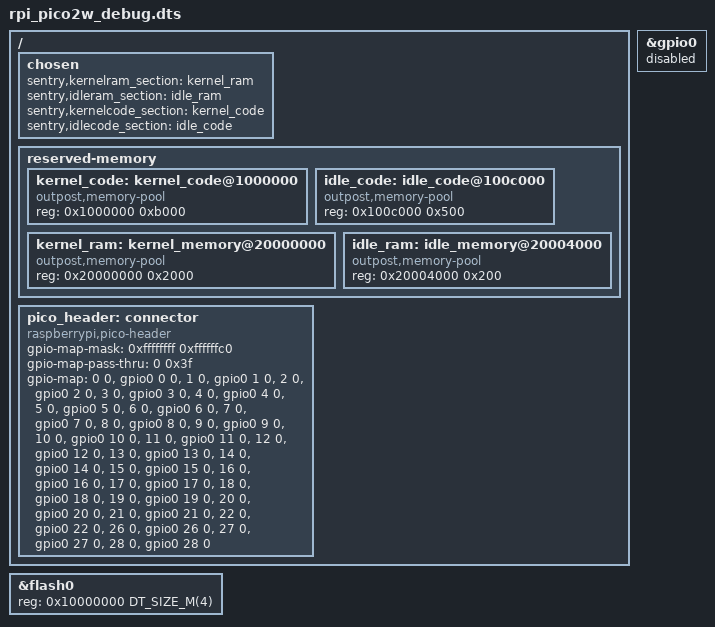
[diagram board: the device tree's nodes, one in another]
/*
 * Copyright (c) 2025 H2Lab development Team
 *
 * SPDX-License-Identifier: Apache-2.0
 */

/{
	chosen {
		sentry,kernelram_section = <&kernel_ram>;
		sentry,idleram_section = <&idle_ram>;
		sentry,kernelcode_section = <&kernel_code>;
		sentry,idlecode_section = <&idle_code>;
	};

	reserved-memory {
		#address-cells = <1>;
		#size-cells = <1>;

		kernel_code: kernel_code@1000000 {
			reg = <0x1000000 0xb000>;
			compatible = "outpost,memory-pool";
		};

		idle_code: idle_code@100c000 {
			reg = <0x100c000 0x500>;
			compatible = "outpost,memory-pool";
		};

		kernel_ram: kernel_memory@20000000 {
			reg = <0x20000000 0x2000>;
			compatible = "outpost,memory-pool";
		};

		idle_ram: idle_memory@20004000 {
			reg = <0x20004000 0x200>;
			compatible = "outpost,memory-pool";
		};
	};

    pico_header: connector {
            compatible = "raspberrypi,pico-header";
            #gpio-cells = <2>;
            gpio-map-mask = <0xffffffff 0xffffffc0>;
            gpio-map-pass-thru = <0 0x3f>;
            gpio-map = <0 0 &gpio0 0 0>,    /* GP0 */
                <1 0 &gpio0 1 0>,       /* GP1 */
                <2 0 &gpio0 2 0>,       /* GP2 */
                <3 0 &gpio0 3 0>,       /* GP3 */
                <4 0 &gpio0 4 0>,       /* GP4 */
                <5 0 &gpio0 5 0>,       /* GP5 */
                <6 0 &gpio0 6 0>,       /* GP6 */
                <7 0 &gpio0 7 0>,       /* GP7 */
                <8 0 &gpio0 8 0>,       /* GP8 */
                <9 0 &gpio0 9 0>,       /* GP9 */
                <10 0 &gpio0 10 0>,     /* GP10 */
                <11 0 &gpio0 11 0>,     /* GP11 */
                <12 0 &gpio0 12 0>,     /* GP12 */
                <13 0 &gpio0 13 0>,     /* GP13 */
                <14 0 &gpio0 14 0>,     /* GP14 */
                <15 0 &gpio0 15 0>,     /* GP15 */
                <16 0 &gpio0 16 0>,     /* GP16 */
                <17 0 &gpio0 17 0>,     /* GP17 */
                <18 0 &gpio0 18 0>,     /* GP18 */
                <19 0 &gpio0 19 0>,     /* GP19 */
                <20 0 &gpio0 20 0>,     /* GP20 */
                <21 0 &gpio0 21 0>,     /* GP21 */
                <22 0 &gpio0 22 0>,     /* GP22 */
                <26 0 &gpio0 26 0>,     /* GP26 */
                <27 0 &gpio0 27 0>,     /* GP27 */
                <28 0 &gpio0 28 0>;     /* GP28 */
    };
};

&flash0 {
        reg = <0x10000000 DT_SIZE_M(4)>;
};

&gpio0 {
    /* needs driver first */
    status = "disabled";
};
